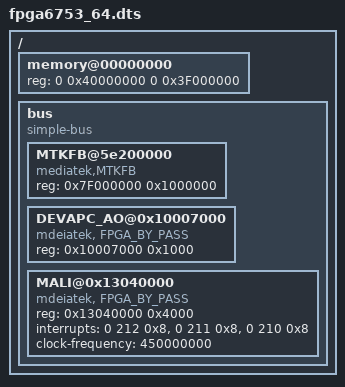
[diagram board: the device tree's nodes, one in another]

/dts-v1/;

/include/ "mt6753.dtsi"

/ {
  memory@00000000 {
		device_type = "memory";
		reg = <0 0x40000000 0 0x3F000000>;
	};

	bus {
		compatible = "simple-bus";
		#address-cells = <1>;
		#size-cells = <1>;
		ranges = <0 0 0 0xffffffff>;

		MTKFB@5e200000 {
			compatible = "mediatek,MTKFB";
			reg = <0x7F000000 0x1000000>;
		};


		DEVAPC_AO@0x10007000 {
			compatible = "mdeiatek, FPGA_BY_PASS";
			reg = <0x10007000 0x1000>;
		};

		MALI@0x13040000 {
			compatible = "mdeiatek, FPGA_BY_PASS";
			reg = <0x13040000 0x4000>;
			interrupts = <0 212 0x8>, <0 211 0x8>, <0 210 0x8>;
			interrupt-names = "JOB", "MMU", "GPU";
			clock-frequency = <450000000>;
		};

		DEVAPC_AO@0x10007000 {
			compatible = "mdeiatek, FPGA_BY_PASS";
			reg = <0x10007000 0x1000>;
  };


	};


};
